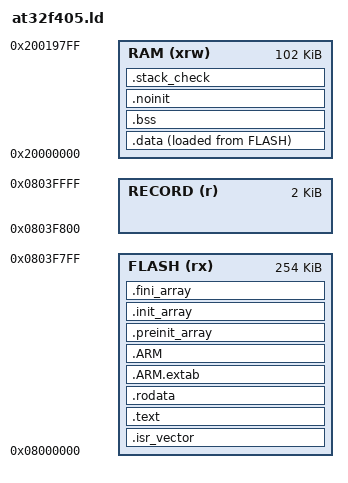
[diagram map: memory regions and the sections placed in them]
/* Where things go in an AT32F405RCT7: 256 KB of flash at 0x08000000 in
 * sectors of 2 KB, 102 KB of RAM at 0x20000000.
 *
 * The last flash sector (0x0803F800) is kept out of the program: it holds
 * the saved record (flash.c). The symbols are the ones Artery's startup
 * file (startup_at32f402_405.s) uses. */

ENTRY(Reset_Handler)

MEMORY
{
    FLASH  (rx)  : ORIGIN = 0x08000000, LENGTH = 254K
    RECORD (r)   : ORIGIN = 0x0803F800, LENGTH = 2K
    RAM    (xrw) : ORIGIN = 0x20000000, LENGTH = 102K
}

_estack = ORIGIN(RAM) + LENGTH(RAM);    /* the stack starts at the top of RAM */
_min_stack = 0x1000;                    /* the link fails if less than this is left for it */

_record_start = ORIGIN(RECORD);
_record_size = LENGTH(RECORD);

SECTIONS
{
    .isr_vector :
    {
        . = ALIGN(4);
        KEEP(*(.isr_vector))
        . = ALIGN(4);
    } >FLASH

    .text :
    {
        . = ALIGN(4);
        *(.text)
        *(.text*)
        *(.glue_7)
        *(.glue_7t)
        *(.eh_frame)
        KEEP(*(.init))
        KEEP(*(.fini))
        . = ALIGN(4);
        _etext = .;
    } >FLASH

    .rodata :
    {
        . = ALIGN(4);
        *(.rodata)
        *(.rodata*)
        . = ALIGN(4);
    } >FLASH

    .ARM.extab : { *(.ARM.extab* .gnu.linkonce.armextab.*) } >FLASH
    .ARM :
    {
        __exidx_start = .;
        *(.ARM.exidx*)
        __exidx_end = .;
    } >FLASH

    .preinit_array :
    {
        PROVIDE_HIDDEN(__preinit_array_start = .);
        KEEP(*(.preinit_array*))
        PROVIDE_HIDDEN(__preinit_array_end = .);
    } >FLASH
    .init_array :
    {
        PROVIDE_HIDDEN(__init_array_start = .);
        KEEP(*(SORT(.init_array.*)))
        KEEP(*(.init_array*))
        PROVIDE_HIDDEN(__init_array_end = .);
    } >FLASH
    .fini_array :
    {
        PROVIDE_HIDDEN(__fini_array_start = .);
        KEEP(*(SORT(.fini_array.*)))
        KEEP(*(.fini_array*))
        PROVIDE_HIDDEN(__fini_array_end = .);
    } >FLASH

    /* Variables with a starting value: kept in flash, copied to RAM by the
     * startup code. */
    _sidata = LOADADDR(.data);
    .data :
    {
        . = ALIGN(4);
        _sdata = .;
        *(.data)
        *(.data*)
        . = ALIGN(4);
        _edata = .;
    } >RAM AT>FLASH

    /* Variables that start as zero: cleared by the startup code. */
    .bss (NOLOAD) :
    {
        . = ALIGN(4);
        _sbss = .;
        __bss_start__ = _sbss;
        *(.bss)
        *(.bss*)
        *(COMMON)
        . = ALIGN(4);
        _ebss = .;
        __bss_end__ = _ebss;
    } >RAM

    /* Variables nobody touches at start, so they live through a reset:
     * the word that says "go to the bootloader" (port.c). */
    .noinit (NOLOAD) :
    {
        . = ALIGN(4);
        *(.noinit)
        *(.noinit*)
        . = ALIGN(4);
    } >RAM

    /* Nothing is put here; it only makes the link fail when the stack
     * would have less than _min_stack. */
    .stack_check (NOLOAD) :
    {
        . = ALIGN(8);
        PROVIDE(end = .);
        PROVIDE(_end = .);
        . = . + _min_stack;
        . = ALIGN(8);
    } >RAM

    .ARM.attributes 0 : { *(.ARM.attributes) }
}
